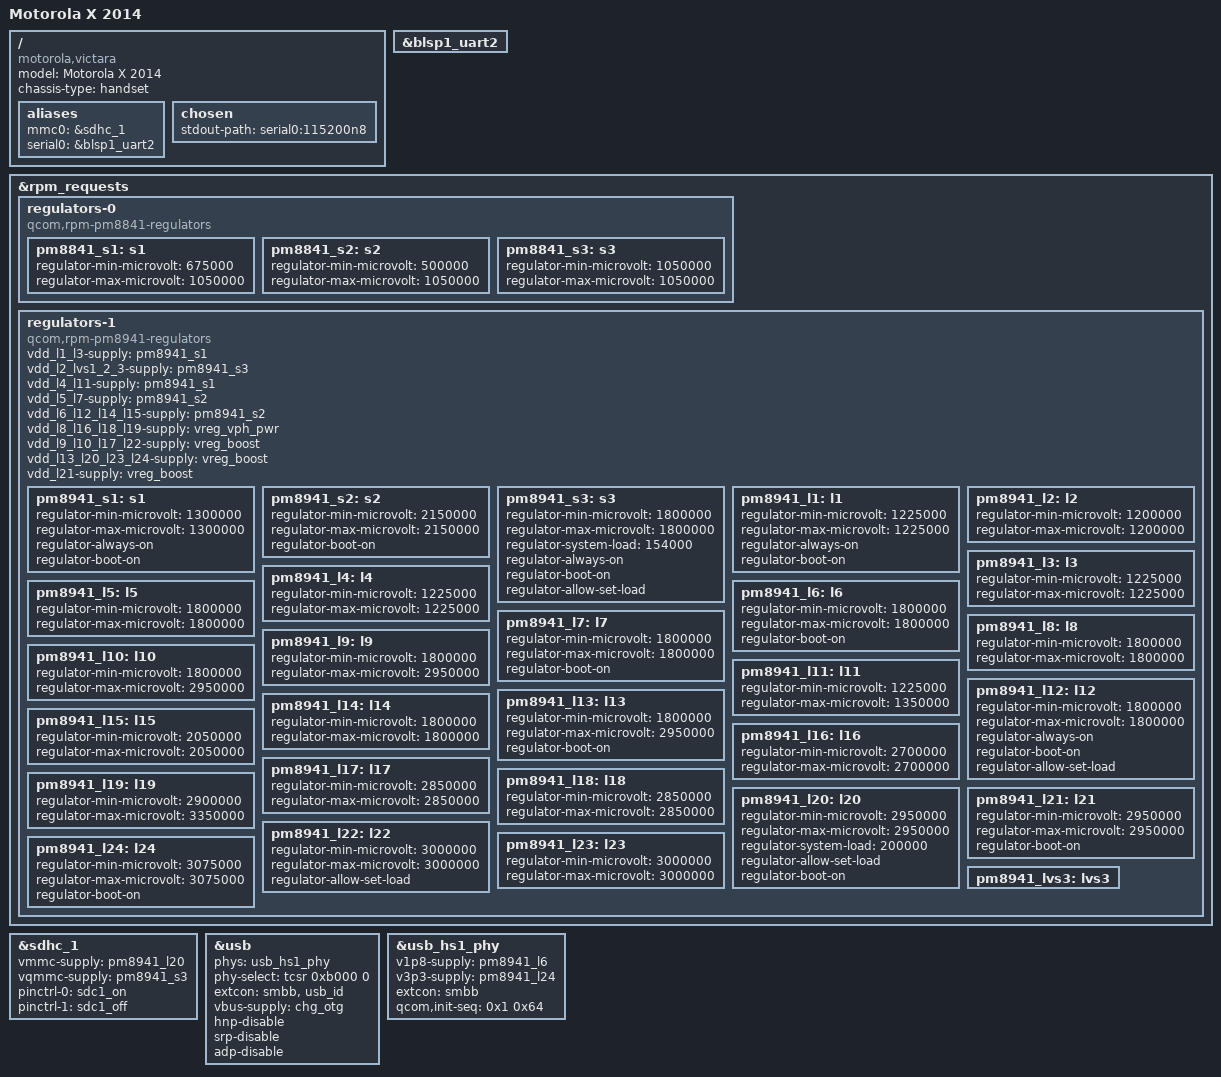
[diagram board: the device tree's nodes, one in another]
// SPDX-License-Identifier: GPL-2.0
#include "qcom-msm8974pro.dtsi"
#include "qcom-pm8841.dtsi"
#include "qcom-pm8941.dtsi"
#include <dt-bindings/input/input.h>
#include <dt-bindings/leds/common.h>
#include <dt-bindings/pinctrl/qcom,pmic-gpio.h>

/ {
	model = "Motorola X 2014";
	compatible = "motorola,victara", "qcom,msm8974pro", "qcom,msm8974";
	chassis-type = "handset";

	aliases {
		mmc0 = &sdhc_1;
		serial0 = &blsp1_uart2;
	};

	chosen {
		stdout-path = "serial0:115200n8";
	};
};

&blsp1_uart2 {
	status = "okay";
};

&rpm_requests {
        regulators-0 {
                compatible = "qcom,rpm-pm8841-regulators";

                pm8841_s1: s1 {
                        regulator-min-microvolt = <675000>;
                        regulator-max-microvolt = <1050000>;
                };

                pm8841_s2: s2 {
                        regulator-min-microvolt = <500000>;
                        regulator-max-microvolt = <1050000>;
                };

                pm8841_s3: s3 {
                        regulator-min-microvolt = <1050000>;
                        regulator-max-microvolt = <1050000>;
                };
        };

        regulators-1 {
                compatible = "qcom,rpm-pm8941-regulators";

                vdd_l1_l3-supply = <&pm8941_s1>;
                vdd_l2_lvs1_2_3-supply = <&pm8941_s3>;
                vdd_l4_l11-supply = <&pm8941_s1>;
                vdd_l5_l7-supply = <&pm8941_s2>;
                vdd_l6_l12_l14_l15-supply = <&pm8941_s2>;
                vdd_l8_l16_l18_l19-supply = <&vreg_vph_pwr>;
                vdd_l9_l10_l17_l22-supply = <&vreg_boost>;
                vdd_l13_l20_l23_l24-supply = <&vreg_boost>;
                vdd_l21-supply = <&vreg_boost>;

                pm8941_s1: s1 {
                        regulator-min-microvolt = <1300000>;
                        regulator-max-microvolt = <1300000>;

                        regulator-always-on;
                        regulator-boot-on;
                };

                pm8941_s2: s2 {
                        regulator-min-microvolt = <2150000>;
                        regulator-max-microvolt = <2150000>;

                        regulator-boot-on;
                };

                pm8941_s3: s3 {
                        regulator-min-microvolt = <1800000>;
                        regulator-max-microvolt = <1800000>;
                        regulator-system-load = <154000>;

                        regulator-always-on;
                        regulator-boot-on;
                        regulator-allow-set-load;
                };

                pm8941_l1: l1 {
                        regulator-min-microvolt = <1225000>;
                        regulator-max-microvolt = <1225000>;

                        regulator-always-on;
                        regulator-boot-on;
                };

                pm8941_l2: l2 {
                        regulator-min-microvolt = <1200000>;
                        regulator-max-microvolt = <1200000>;
                };

                pm8941_l3: l3 {
                        regulator-min-microvolt = <1225000>;
                        regulator-max-microvolt = <1225000>;
                };

                pm8941_l4: l4 {
                        regulator-min-microvolt = <1225000>;
                        regulator-max-microvolt = <1225000>;
                };

                pm8941_l5: l5 {
                        regulator-min-microvolt = <1800000>;
                        regulator-max-microvolt = <1800000>;
                };

                pm8941_l6: l6 {
                        regulator-min-microvolt = <1800000>;
                        regulator-max-microvolt = <1800000>;

                        regulator-boot-on;
                };

                pm8941_l7: l7 {
                        regulator-min-microvolt = <1800000>;
                        regulator-max-microvolt = <1800000>;

                        regulator-boot-on;
                };

                pm8941_l8: l8 {
                        regulator-min-microvolt = <1800000>;
                        regulator-max-microvolt = <1800000>;
                };

                pm8941_l9: l9 {
                        regulator-min-microvolt = <1800000>;
                        regulator-max-microvolt = <2950000>;
                };

                pm8941_l10: l10 {
                        regulator-min-microvolt = <1800000>;
                        regulator-max-microvolt = <2950000>;
                };

                pm8941_l11: l11 {
                        regulator-min-microvolt = <1225000>;
                        regulator-max-microvolt = <1350000>;
                };

                pm8941_l12: l12 {
                        regulator-min-microvolt = <1800000>;
                        regulator-max-microvolt = <1800000>;

                        regulator-always-on;
                        regulator-boot-on;
                        regulator-allow-set-load;
                };

                pm8941_l13: l13 {
                        regulator-min-microvolt = <1800000>;
                        regulator-max-microvolt = <2950000>;

                        regulator-boot-on;
                };

                pm8941_l14: l14 {
                        regulator-min-microvolt = <1800000>;
                        regulator-max-microvolt = <1800000>;
                };

                pm8941_l15: l15 {
                        regulator-min-microvolt = <2050000>;
                        regulator-max-microvolt = <2050000>;
                };

                pm8941_l16: l16 {
                        regulator-min-microvolt = <2700000>;
                        regulator-max-microvolt = <2700000>;
                };

                pm8941_l17: l17 {
                        regulator-min-microvolt = <2850000>;
                        regulator-max-microvolt = <2850000>;
                };

                pm8941_l18: l18 {
                        regulator-min-microvolt = <2850000>;
                        regulator-max-microvolt = <2850000>;
                };

                pm8941_l19: l19 {
                        regulator-min-microvolt = <2900000>;
                        regulator-max-microvolt = <3350000>;
                };

                pm8941_l20: l20 {
                        regulator-min-microvolt = <2950000>;
                        regulator-max-microvolt = <2950000>;

                        regulator-system-load = <200000>;
                        regulator-allow-set-load;
                        regulator-boot-on;
                };

                pm8941_l21: l21 {
                        regulator-min-microvolt = <2950000>;
                        regulator-max-microvolt = <2950000>;

                        regulator-boot-on;
                };

                pm8941_l22: l22 {
                        regulator-min-microvolt = <3000000>;
                        regulator-max-microvolt = <3000000>;
                        regulator-allow-set-load;
                };

                pm8941_l23: l23 {
                        regulator-min-microvolt = <3000000>;
                        regulator-max-microvolt = <3000000>;
                };

                pm8941_l24: l24 {
                        regulator-min-microvolt = <3075000>;
                        regulator-max-microvolt = <3075000>;

                        regulator-boot-on;
                };

                pm8941_lvs3: lvs3 {};
        };
};

&sdhc_1 {
        status = "okay";
                        
        vmmc-supply = <&pm8941_l20>;
        vqmmc-supply = <&pm8941_s3>;

        pinctrl-names = "default", "sleep";
        pinctrl-0 = <&sdc1_on>;
        pinctrl-1 = <&sdc1_off>;
};

&usb {          
        phys = <&usb_hs1_phy>;
        phy-select = <&tcsr 0xb000 0>;
        extcon = <&smbb>, <&usb_id>;
        vbus-supply = <&chg_otg>;

        hnp-disable;
        srp-disable;
        adp-disable;    
                        
        status = "okay";
};              

&usb_hs1_phy {  
        status = "okay";
                        
        v1p8-supply = <&pm8941_l6>;
        v3p3-supply = <&pm8941_l24>;
        
        extcon = <&smbb>;
        qcom,init-seq = /bits/ 8 <0x1 0x64>;
};
